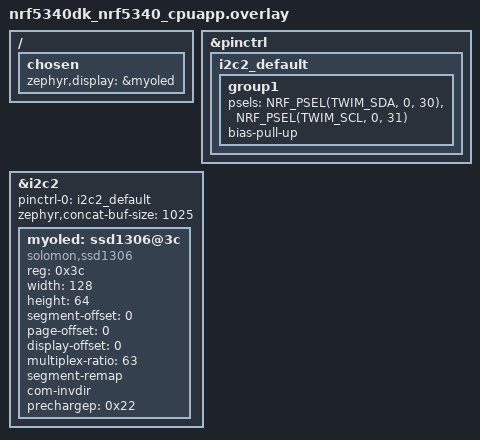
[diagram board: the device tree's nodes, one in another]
/*
 * Copyright (c) 2026 Ravi
 * SPDX-License-Identifier: Apache-2.0
 */

/ {
	chosen {
		zephyr,display = &myoled;
	};
};

&pinctrl {
	i2c2_default: i2c2_default {
		group1 {
			psels = <NRF_PSEL(TWIM_SDA, 0, 30)>,
			        <NRF_PSEL(TWIM_SCL, 0, 31)>;
			bias-pull-up;
		};
	};
};

&i2c2 {
	status = "okay";
	pinctrl-0 = <&i2c2_default>;
	pinctrl-names = "default";
	zephyr,concat-buf-size = <1025>;

	myoled: ssd1306@3c {
		compatible = "solomon,ssd1306";
		reg = <0x3c>;
		width = <128>;
		height = <64>;
		segment-offset = <0>;
		page-offset = <0>;
		display-offset = <0>;
		multiplex-ratio = <63>;
		segment-remap;
		com-invdir;
		prechargep = <0x22>;
	};
};
